# SIMG301M113WIH register map
Vendor: Silicon Labs; Series: Si; File version: B
Registers are 32-bit, read-write, reset 0x0 unless marked. A register's access mark holds for its fields unless they carry their own. Offsets are from the block's base; [hi:lo] are bit positions; {n}, {i} and the like mark numbered series; 'fields as' and 'values as' point back to an identical list.

## BURAM_NS — BURAM_NS Registers
Base 0x40878000
Same registers: BURAM_S 0x50878000
{0x0+4i} RET{i}_REG (i=0..31)
  [31:0] RETREG — Latch based Retention register

## BURTC_NS — BURTC_NS Registers
Base 0x40864000
Same registers: BURTC_S 0x50864000
0x00 IPVERSION ro reset 0x1
  [31:0] IPVERSION — IP Version ID
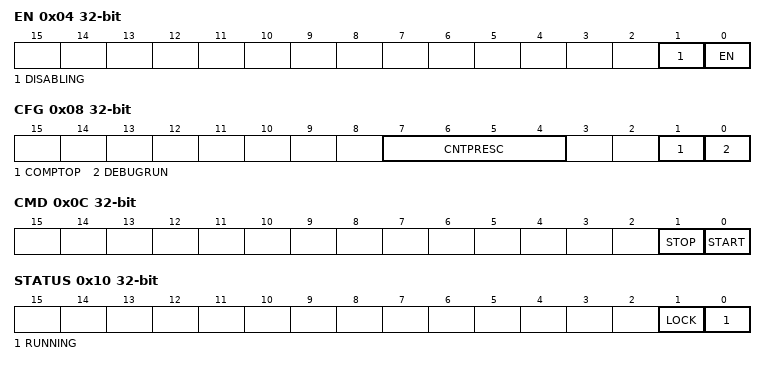
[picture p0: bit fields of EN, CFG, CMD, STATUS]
0x04 EN
  [1] DISABLING ro — Disablement busy status
  [0] EN — BURTC Enable
0x08 CFG
  [7:4] CNTPRESC — Counter prescaler value.
    0=DIV1 (CLK_CNT = (BURTC LF CLK)/1); 1=DIV2 (CLK_CNT = (BURTC LF CLK)/2); 2=DIV4 (CLK_CNT = (BURTC LF CLK)/4); 3=DIV8 (CLK_CNT = (BURTC LF CLK)/8); 4=DIV16 (CLK_CNT = (BURTC LF CLK)/16); 5=DIV32 (CLK_CNT = (BURTC LF CLK)/32); 6=DIV64 (CLK_CNT = (BURTC LF CLK)/64); 7=DIV128 (CLK_CNT = (BURTC LF CLK)/128); 8=DIV256 (CLK_CNT = (BURTC LF CLK)/256); 9=DIV512 (CLK_CNT = (BURTC LF CLK)/512); 10=DIV1024 (CLK_CNT = (BURTC LF CLK)/1024); 11=DIV2048 (CLK_CNT = (BURTC LF CLK)/2048); 12=DIV4096 (CLK_CNT = (BURTC LF CLK)/4096); 13=DIV8192 (CLK_CNT = (BURTC LF CLK)/8192); 14=DIV16384 (CLK_CNT = (BURTC LF CLK)/16384); 15=DIV32768 (CLK_CNT = (BURTC LF CLK)/32768)
  [1] COMPTOP — Compare Channel is Top Value
    0=DISABLE (The top value of the BURTC is 4294967295 (0xFFFFFFFF)); 1=ENABLE (The top value of the BURTC is given by COMP)
  [0] DEBUGRUN — Debug Mode Run Enable
    0=BURTC is frozen in debug mode; 1=BURTC is running in debug mode
0x0C CMD wo
  [1] STOP — Stop BURTC counter
  [0] START — Start BURTC counter
0x10 STATUS ro
  [1] LOCK — Configuration Lock Status
    0=UNLOCKED (All BURTC lockable registers are unlocked.); 1=LOCKED (All BURTC lockable registers are locked.)
  [0] RUNNING — BURTC running status
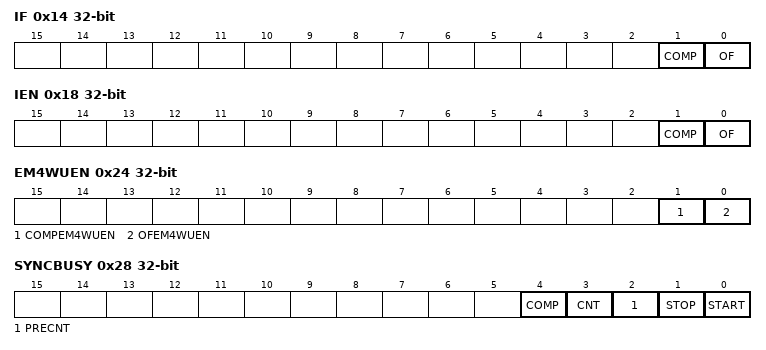
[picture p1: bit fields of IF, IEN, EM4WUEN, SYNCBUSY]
0x14 IF
  [1] COMP — Compare Match Interrupt Flag
  [0] OF — Overflow Interrupt Flag
0x18 IEN
  fields as IF
0x1C PRECNT
  [14:0] PRECNT — Pre-Counter Value
0x20 CNT
  [31:0] CNT — Counter Value
0x24 EM4WUEN
  [1] COMPEM4WUEN — Compare Match EM4 Wakeup Enable
  [0] OFEM4WUEN — Overflow EM4 Wakeup Enable
0x28 SYNCBUSY ro
  [4] COMP — Sync busy for COMP
  [3] CNT — Sync busy for CNT
  [2] PRECNT — Sync busy for PRECNT
  [1] STOP — Sync busy for STOP
  [0] START — Sync busy for START
0x2C LOCK wo reset 0xAEE8
  [15:0] LOCKKEY — Configuration Lock Key
    0xAEE8=UNLOCK (Write to unlock all BURTC lockable registers)
0x30 COMP
  [31:0] COMP — Compare Value

## DEVINFO_NS — DEVINFO_NS Registers
Base 0x0FE08000
Same registers: DEVINFO_S 0x1FE08000
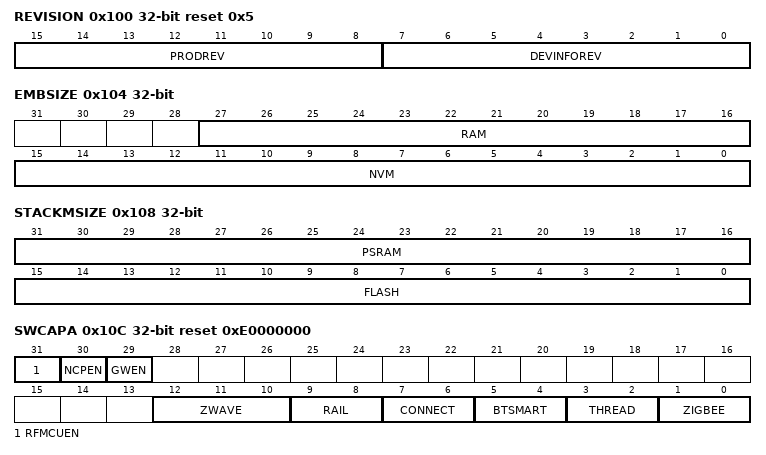
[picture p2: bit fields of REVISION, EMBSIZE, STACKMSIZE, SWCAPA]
0x100 REVISION ro reset 0x5 — Version of the device info structure being used
  [15:8] PRODREV — Production Revision
  [7:0] DEVINFOREV — DI Page Version
0x104 EMBSIZE ro — Embedded memory size information
  [27:16] RAM — Internal RAM memory size
  [15:0] NVM — Internal NVM memory size
0x108 STACKMSIZE ro — Co-packaged memory size information
  [31:16] PSRAM — Co-packaged PSRAM Size
  [15:0] FLASH — Co-packaged Flash Size
0x10C SWCAPA ro reset 0xE0000000 — Software Capability
  [31] RFMCUEN — RF-MCU
  [30] NCPEN — NCP
  [29] GWEN — Gateway
  [12:10] ZWAVE — Z-Wave Capability
    0=LEVEL0 (Z-Wave stack capability not available); 1=LEVEL1 (Z-Wave and Z-Wave LR stack); 2=LEVEL2 (Z-Wave stack capability without LR)
  [9:8] RAIL — RAIL Capability
    0=LEVEL0 (RAIL capability not available); 1=LEVEL1 (RAIL enabled); 2=LEVEL2 (N/A); 3=LEVEL3 (N/A)
  [7:6] CONNECT — Connect Capability
    0=LEVEL0 (Connect stack capability not available); 1=LEVEL1 (Connect enabled); 2=LEVEL2 (N/A); 3=LEVEL3 (N/A)
  [5:4] BTSMART — Bluetooth Smart Capability
    0=LEVEL0 (Bluetooth SMART stack capability not available); 1=LEVEL1 (Bluetooth SMART enabled); 2=LEVEL2 (N/A); 3=LEVEL3 (N/A)
  [3:2] THREAD — Thread Capability
    0=LEVEL0 (Thread stack capability not available); 1=LEVEL1 (Thread stack enabled); 2=LEVEL2 (N/A); 3=LEVEL3 (N/A)
  [1:0] ZIGBEE — Zigbee Capability
    0=LEVEL0 (Zigbee stack capability not available); 1=LEVEL1 (GreenPower only); 2=LEVEL2 (Zigbee and GreenPower); 3=LEVEL3 (Zigbee only)
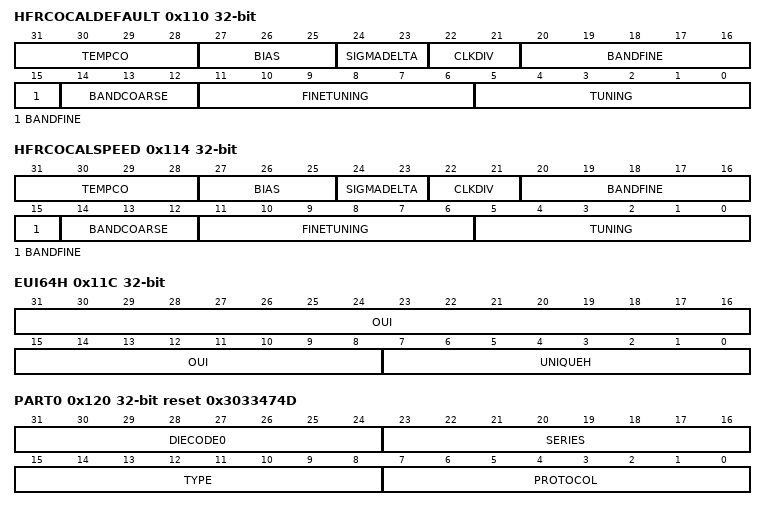
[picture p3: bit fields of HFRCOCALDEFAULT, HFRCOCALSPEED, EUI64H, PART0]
0x110 HFRCOCALDEFAULT ro — HFRCODPLL calibrated 38MHz setting
  [31:28] TEMPCO — Tempco Trim
  [27:25] BIAS — Bias Current Setting
  [24:23] SIGMADELTA — Sigma Delta Setting
  [22:21] CLKDIV — HFRCO Clock Output Divider
  [20:15] BANDFINE — Band Fine Value
  [14:12] BANDCOARSE — Band Coarse Value
  [11:6] FINETUNING — Fine Tuning Value
  [5:0] TUNING — Coarse Tuning Value
0x114 HFRCOCALSPEED ro — HFRCODPLL calibrated 100MHz setting
  fields as HFRCOCALDEFAULT
0x118 EUI64L ro — MA-L compliant EUI64 Unique Identifier (low bits)
  [31:0] UNIQUEL
0x11C EUI64H ro — MA-L compliant EUI64 OUI and Unique Identifier (high bits)
  [31:8] OUI, [7:0] UNIQUEH
0x120 PART0 ro reset 0x3033474D — Part Description
  [31:24] DIECODE0 — Die Code
  [23:16] SERIES — Series Identifier
  [15:8] TYPE — Device Type
  [7:0] PROTOCOL — Main Protocol
    66=BLUETOOTH; 70=PROPRIETARY; 77=FIFTEENPFOUR (15.4); 80=PEARL; 87=WIFI; 90=ZWAVE
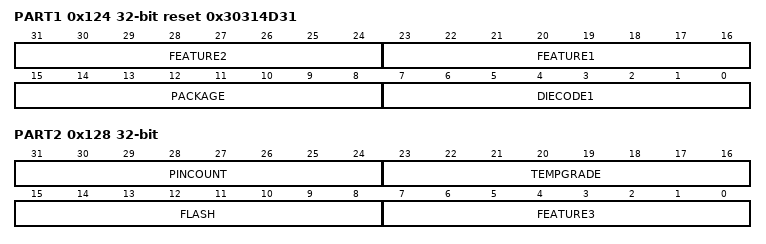
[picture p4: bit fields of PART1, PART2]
0x124 PART1 ro reset 0x30314D31 — Part Description
  [31:24] FEATURE2 — Device Feature
    48=NOLED (LED option not available); 49=LED (LED option available)
  [23:16] FEATURE1 — Device Feature
  [15:8] PACKAGE — Package Type
  [7:0] DIECODE1 — Die Code
0x128 PART2 ro — Part Description
  [31:24] PINCOUNT
  [23:16] TEMPGRADE — Temperature Grade
  [15:8] FLASH — Flash Size
  [7:0] FEATURE3 — Device Feature
0x1FC LEGACY ro reset 0x810000 — Hardcoded value to signal this is a Series-3 device with DI/CC access through the SE
  [31:0] DATALEGACY — LEGACY data
